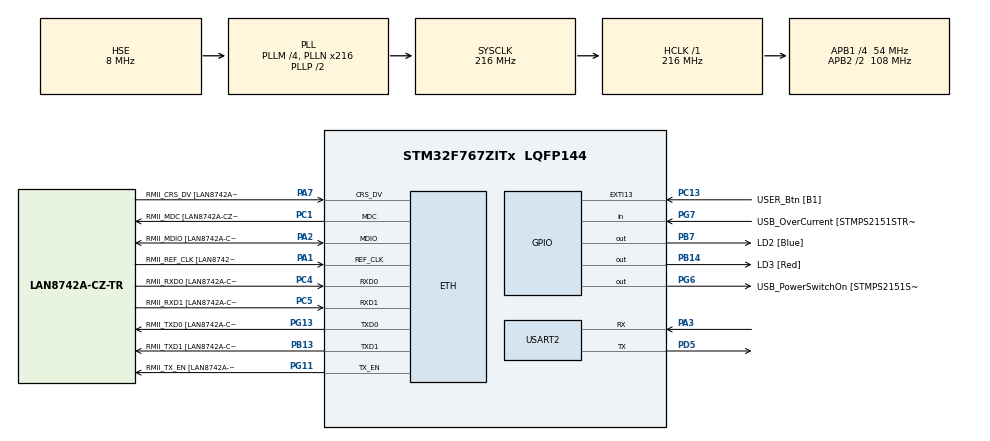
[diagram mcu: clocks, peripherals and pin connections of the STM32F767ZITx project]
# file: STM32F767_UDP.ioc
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CORTEX_M7.CPU_DCache=Enabled
CORTEX_M7.CPU_ICache=Enabled
CORTEX_M7.MPU_Control=__NULL
ETH.MACAddr=B0\:0B\:50\:00\:01\:17
ETH.MediaInterface=ETH_MEDIA_INTERFACE_RMII
ETH.PHY_Name=LAN8742A_PHY_ADDRESS
ETH.PHY_Value=0
ETH.PhyAddress=0
LWIP.GATEWAY_ADDRESS=192.168.000.001
LWIP.IP_ADDRESS=192.168.000.010
LWIP.LWIP_DHCP=0
LWIP.NETMASK_ADDRESS=255.255.255.000
LWIP.Version=v2.0.3_Cube
Mcu.Family=STM32F7
Mcu.Name=STM32F767ZITx
Mcu.Package=LQFP144
NVIC.PriorityGroup=NVIC_PRIORITYGROUP_4
PA1.GPIO_Label=RMII_REF_CLK [LAN8742A-CZ-TR_REFCLK0]
PA1.Mode=RMII
PA1.Signal=ETH_REF_CLK
PA10.GPIO_Label=USB_ID
PA10.Signal=USB_OTG_FS_ID
PA11.GPIO_Label=USB_DM
PA11.Signal=USB_OTG_FS_DM
PA12.GPIO_Label=USB_DP
PA12.Signal=USB_OTG_FS_DP
PA13.GPIO_Label=TMS
PA13.Mode=Serial_Wire
PA13.Signal=SYS_JTMS-SWDIO
PA14.GPIO_Label=TCK
PA14.Mode=Serial_Wire
PA14.Signal=SYS_JTCK-SWCLK
PA2.GPIO_Label=RMII_MDIO [LAN8742A-CZ-TR_MDIO]
PA2.Mode=RMII
PA2.Signal=ETH_MDIO
PA3.Mode=Asynchronous
PA3.Signal=USART2_RX
PA7.GPIO_Label=RMII_CRS_DV [LAN8742A-CZ-TR_CRS_DV]
PA7.Mode=RMII
PA7.Signal=ETH_CRS_DV
PA8.GPIO_Label=USB_SOF [TP1]
PA8.Signal=USB_OTG_FS_SOF
PA9.GPIO_Label=USB_VBUS
PA9.Signal=USB_OTG_FS_VBUS
PB13.GPIO_Label=RMII_TXD1 [LAN8742A-CZ-TR_TXD1]
PB13.Mode=RMII
PB13.Signal=ETH_TXD1
PB14.GPIO_Label=LD3 [Red]
PB14.Signal=GPIO_Output
PB3.GPIO_Label=SWO
PB3.Signal=SYS_JTDO-SWO
PB7.GPIO_Label=LD2 [Blue]
PB7.Signal=GPIO_Output
PC1.GPIO_Label=RMII_MDC [LAN8742A-CZ-TR_MDC]
PC1.Mode=RMII
PC1.Signal=ETH_MDC
PC13.GPIO_Label=USER_Btn [B1]
PC13.Signal=GPXTI13
PC14/OSC32_IN.Mode=LSE-External-Oscillator
PC14/OSC32_IN.Signal=RCC_OSC32_IN
PC15/OSC32_OUT.Mode=LSE-External-Oscillator
PC15/OSC32_OUT.Signal=RCC_OSC32_OUT
PC4.GPIO_Label=RMII_RXD0 [LAN8742A-CZ-TR_RXD0]
PC4.Mode=RMII
PC4.Signal=ETH_RXD0
PC5.GPIO_Label=RMII_RXD1 [LAN8742A-CZ-TR_RXD1]
PC5.Mode=RMII
PC5.Signal=ETH_RXD1
PD5.Mode=Asynchronous
PD5.Signal=USART2_TX
PD8.GPIO_Label=STLK_RX [STM32F103CBT6_PA3]
PD8.Signal=USART3_TX
PD9.GPIO_Label=STLK_TX [STM32F103CBT6_PA2]
PD9.Signal=USART3_RX
PG11.GPIO_Label=RMII_TX_EN [LAN8742A-CZ-TR_TXEN]
PG11.Mode=RMII
PG11.Signal=ETH_TX_EN
PG13.GPIO_Label=RMII_TXD0 [LAN8742A-CZ-TR_TXD0]
PG13.Mode=RMII
PG13.Signal=ETH_TXD0
PG6.GPIO_Label=USB_PowerSwitchOn [STMPS2151STR_EN]
PG6.Signal=GPIO_Output
PG7.GPIO_Label=USB_OverCurrent [STMPS2151STR_FAULT]
PG7.Signal=GPIO_Input
PH0/OSC_IN.GPIO_Label=MCO [STM32F103CBT6_PA8]
PH0/OSC_IN.Mode=HSE-External-Clock-Source
PH0/OSC_IN.Signal=RCC_OSC_IN
PH1/OSC_OUT.Mode=HSE-External-Clock-Source
PH1/OSC_OUT.Signal=RCC_OSC_OUT
ProjectManager.HeapSize=0x200
ProjectManager.StackSize=0x400
ProjectManager.TargetToolchain=TrueSTUDIO
RCC.48MHZClocksFreq_Value=24000000
RCC.AHBFreq_Value=216000000
RCC.APB1CLKDivider=RCC_HCLK_DIV4
RCC.APB1Freq_Value=54000000
RCC.APB1TimFreq_Value=108000000
RCC.APB2CLKDivider=RCC_HCLK_DIV2
RCC.APB2Freq_Value=108000000
RCC.APB2TimFreq_Value=216000000
RCC.CortexFreq_Value=216000000
RCC.HCLKFreq_Value=216000000
RCC.HSE_VALUE=8000000
RCC.HSI_VALUE=16000000
RCC.PLLM=4
RCC.PLLMUL=RCC_PLL_MUL9
RCC.PLLN=216
RCC.PLLQ=4
RCC.PLLSourceVirtual=RCC_PLLSOURCE_HSE
RCC.PRESCALERUSB=RCC_USBCLKSOURCE_PLL_DIV1_5
RCC.SYSCLKFreq_VALUE=216000000
RCC.SYSCLKSource=RCC_SYSCLKSOURCE_PLLCLK
RCC.SYSCLKSourceVirtual=RCC_SYSCLKSOURCE_PLLCLK
RCC.USBFreq_Value=108000000
RCC.VCOOutputFreq_Value=432000000
USART2.VirtualMode-Asynchronous=VM_ASYNC
USART2.WordLength=WORDLENGTH_8B
VP_LWIP_VS_Enabled.Mode=Enabled
board=NUCLEO-F767ZI

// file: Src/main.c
/**
  ******************************************************************************
  * @file           : main.c
  * @brief          : Main program body
  ******************************************************************************
  * This notice applies to any and all portions of this file
  * that are not between comment pairs USER CODE BEGIN and
  * USER CODE END. Other portions of this file, whether
  * inserted by the user or by software development tools
  * are owned by their respective copyright owners.
  *
  * Copyright (c) 2018 STMicroelectronics International N.V.
  * All rights reserved.
  *
  * Redistribution and use in source and binary forms, with or without
  * modification, are permitted, provided that the following conditions are met:
  *
  * 1. Redistribution of source code must retain the above copyright notice,
  *    this list of conditions and the following disclaimer.
  * 2. Redistributions in binary form must reproduce the above copyright notice,
  *    this list of conditions and the following disclaimer in the documentation
  *    and/or other materials provided with the distribution.
  * 3. Neither the name of STMicroelectronics nor the names of other
  *    contributors to this software may be used to endorse or promote products
  *    derived from this software without specific written permission.
  * 4. This software, including modifications and/or derivative works of this
  *    software, must execute solely and exclusively on microcontroller or
  *    microprocessor devices manufactured by or for STMicroelectronics.
  * 5. Redistribution and use of this software other than as permitted under
  *    this license is void and will automatically terminate your rights under
  *    this license.
  *
  * THIS SOFTWARE IS PROVIDED BY STMICROELECTRONICS AND CONTRIBUTORS "AS IS"
  * AND ANY EXPRESS, IMPLIED OR STATUTORY WARRANTIES, INCLUDING, BUT NOT
  * LIMITED TO, THE IMPLIED WARRANTIES OF MERCHANTABILITY, FITNESS FOR A
  * PARTICULAR PURPOSE AND NON-INFRINGEMENT OF THIRD PARTY INTELLECTUAL PROPERTY
  * RIGHTS ARE DISCLAIMED TO THE FULLEST EXTENT PERMITTED BY LAW. IN NO EVENT
  * SHALL STMICROELECTRONICS OR CONTRIBUTORS BE LIABLE FOR ANY DIRECT, INDIRECT,
  * INCIDENTAL, SPECIAL, EXEMPLARY, OR CONSEQUENTIAL DAMAGES (INCLUDING, BUT NOT
  * LIMITED TO, PROCUREMENT OF SUBSTITUTE GOODS OR SERVICES; LOSS OF USE, DATA,
  * OR PROFITS; OR BUSINESS INTERRUPTION) HOWEVER CAUSED AND ON ANY THEORY OF
  * LIABILITY, WHETHER IN CONTRACT, STRICT LIABILITY, OR TORT (INCLUDING
  * NEGLIGENCE OR OTHERWISE) ARISING IN ANY WAY OUT OF THE USE OF THIS SOFTWARE,
  * EVEN IF ADVISED OF THE POSSIBILITY OF SUCH DAMAGE.
  *
  ******************************************************************************
  */
#include "main.h"
#include "stm32f7xx_hal.h"
#include "lwip.h"
#include "usart.h"
#include "gpio.h"
#include "serial_print.h"// USART2 TX==PD5, RX==PA3
#include "udp_echoclient.h"
#include "XcpBasic.h"

/* USER CODE BEGIN PV */
/* Private variables ---------------------------------------------------------*/

/* USER CODE END PV */

void SystemClock_Config(void);

/* USER CODE BEGIN PFP */
/* Private function prototypes -----------------------------------------------*/

/* USER CODE END PFP */

int main(void)
{
  /* USER CODE BEGIN 1 */
	unsigned counter=0;//used for delaying  udp trasmission events
  /* USER CODE END 1 */

  /* Enable I-Cache-------------------------------------------------------------*/
  SCB_EnableICache();

  /* Enable D-Cache-------------------------------------------------------------*/
  SCB_EnableDCache();

  /* MCU Configuration----------------------------------------------------------*/

  /* Reset of all peripherals, Initializes the Flash interface and the Systick. */
  HAL_Init();

  /* Configure the system clock */
  SystemClock_Config();

  /* Initialize all configured peripherals */
  MX_GPIO_Init();
  MX_LWIP_Init();
  MX_USART2_UART_Init();
  /* USER CODE BEGIN 2 */
  serial_print(clear_screen);
  serial_print("System initialized!");

  udp_echoclient_connect();
  /* USER CODE END 2 */

  serial_print("Going to main loop!");
  /* Infinite loop */
  while (1)
  {
	  ethernetif_input(&gnetif);

	  if(counter==10000000)
	  {

		  udp_echoclient_send("Main Loop");
		  counter=0;

	  }

	  counter++;
  }

}

void SystemClock_Config(void)
{

  RCC_OscInitTypeDef RCC_OscInitStruct;
  RCC_ClkInitTypeDef RCC_ClkInitStruct;
  RCC_PeriphCLKInitTypeDef PeriphClkInitStruct;

    /**Configure the main internal regulator output voltage
    */
  __HAL_RCC_PWR_CLK_ENABLE();

  __HAL_PWR_VOLTAGESCALING_CONFIG(PWR_REGULATOR_VOLTAGE_SCALE1);

    /**Initializes the CPU, AHB and APB busses clocks
    */
  RCC_OscInitStruct.OscillatorType = RCC_OSCILLATORTYPE_HSE;
  RCC_OscInitStruct.HSEState = RCC_HSE_BYPASS;
  RCC_OscInitStruct.PLL.PLLState = RCC_PLL_ON;
  RCC_OscInitStruct.PLL.PLLSource = RCC_PLLSOURCE_HSE;
  RCC_OscInitStruct.PLL.PLLM = 4;
  RCC_OscInitStruct.PLL.PLLN = 216;
  RCC_OscInitStruct.PLL.PLLP = RCC_PLLP_DIV2;
  RCC_OscInitStruct.PLL.PLLQ = 4;
  if (HAL_RCC_OscConfig(&RCC_OscInitStruct) != HAL_OK)
  {
    _Error_Handler(__FILE__, __LINE__);
  }

    /**Activate the Over-Drive mode
    */
  if (HAL_PWREx_EnableOverDrive() != HAL_OK)
  {
    _Error_Handler(__FILE__, __LINE__);
  }

    /**Initializes the CPU, AHB and APB busses clocks
    */
  RCC_ClkInitStruct.ClockType = RCC_CLOCKTYPE_HCLK|RCC_CLOCKTYPE_SYSCLK
                              |RCC_CLOCKTYPE_PCLK1|RCC_CLOCKTYPE_PCLK2;
  RCC_ClkInitStruct.SYSCLKSource = RCC_SYSCLKSOURCE_PLLCLK;
  RCC_ClkInitStruct.AHBCLKDivider = RCC_SYSCLK_DIV1;
  RCC_ClkInitStruct.APB1CLKDivider = RCC_HCLK_DIV4;
  RCC_ClkInitStruct.APB2CLKDivider = RCC_HCLK_DIV2;

  if (HAL_RCC_ClockConfig(&RCC_ClkInitStruct, FLASH_LATENCY_7) != HAL_OK)
  {
    _Error_Handler(__FILE__, __LINE__);
  }

  PeriphClkInitStruct.PeriphClockSelection = RCC_PERIPHCLK_USART2;
  PeriphClkInitStruct.Usart2ClockSelection = RCC_USART2CLKSOURCE_PCLK1;
  if (HAL_RCCEx_PeriphCLKConfig(&PeriphClkInitStruct) != HAL_OK)
  {
    _Error_Handler(__FILE__, __LINE__);
  }

    /**Configure the Systick interrupt time
    */
  HAL_SYSTICK_Config(HAL_RCC_GetHCLKFreq()/1000);

    /**Configure the Systick
    */
  HAL_SYSTICK_CLKSourceConfig(SYSTICK_CLKSOURCE_HCLK);

  /* SysTick_IRQn interrupt configuration */
  HAL_NVIC_SetPriority(SysTick_IRQn, 0, 0);
}

void _Error_Handler(char *file, int line)
{
  while(1)
  {
  }
}

/************************ (C) COPYRIGHT STMicroelectronics *****END OF FILE****/
